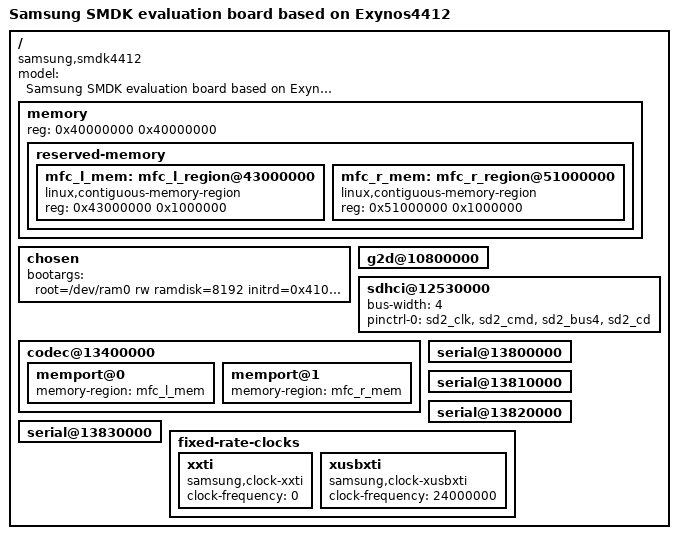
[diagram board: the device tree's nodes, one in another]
/*
 * Samsung's Exynos4412 based SMDK board device tree source
 *
 * Copyright (c) 2012-2013 Samsung Electronics Co., Ltd.
 *		http://www.samsung.com
 *
 * Device tree source file for Samsung's SMDK4412 board which is based on
 * Samsung's Exynos4412 SoC.
 *
 * This program is free software; you can redistribute it and/or modify
 * it under the terms of the GNU General Public License version 2 as
 * published by the Free Software Foundation.
*/

/dts-v1/;
/include/ "exynos4412.dtsi"

/ {
	model = "Samsung SMDK evaluation board based on Exynos4412";
	compatible = "samsung,smdk4412", "samsung,exynos4412";

	memory {
		reg = <0x40000000 0x40000000>;

		reserved-memory {
			#address-cells = <1>;
			#size-cells = <1>;

			mfc_l_mem: mfc_l_region@43000000 {
				compatible = "linux,contiguous-memory-region", "reserved-memory-region";
				reg = <0x43000000 0x1000000>;
			};

			mfc_r_mem: mfc_r_region@51000000 {
				compatible = "linux,contiguous-memory-region", "reserved-memory-region";
				reg = <0x51000000 0x1000000>;
			};
		};
	};

	chosen {
		bootargs ="root=/dev/ram0 rw ramdisk=8192 initrd=0x41000000,8M console=ttySAC1,115200 init=/linuxrc";
	};

	g2d@10800000 {
		status = "okay";
	};

	g2d@10800000 {
		status = "okay";
	};

	sdhci@12530000 {
		bus-width = <4>;
		pinctrl-0 = <&sd2_clk &sd2_cmd &sd2_bus4 &sd2_cd>;
		pinctrl-names = "default";
		status = "okay";
	};

	codec@13400000 {
		status = "okay";

		memport@0 {
			memory-region = <&mfc_l_mem>;
		};

		memport@1 {
			memory-region = <&mfc_r_mem>;
		};
	};

	serial@13800000 {
		status = "okay";
	};

	serial@13810000 {
		status = "okay";
	};

	serial@13820000 {
		status = "okay";
	};

	serial@13830000 {
		status = "okay";
	};

	fixed-rate-clocks {
		xxti {
			compatible = "samsung,clock-xxti";
			clock-frequency = <0>;
		};

		xusbxti {
			compatible = "samsung,clock-xusbxti";
			clock-frequency = <24000000>;
		};
	};
};
